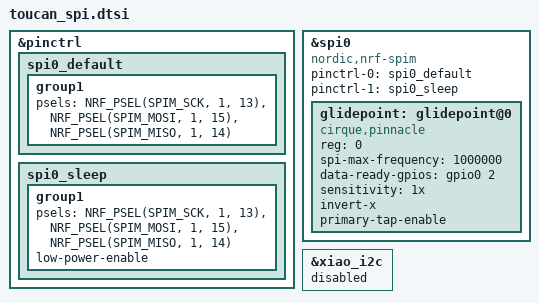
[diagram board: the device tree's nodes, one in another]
&pinctrl {
    spi0_default: spi0_default {
        group1 {
            psels = <NRF_PSEL(SPIM_SCK, 1, 13)>,
                    <NRF_PSEL(SPIM_MOSI, 1, 15)>,
                    <NRF_PSEL(SPIM_MISO, 1, 14)>;
        };
    };

    spi0_sleep: spi0_sleep {
        group1: group1 {
            psels = <NRF_PSEL(SPIM_SCK, 1, 13)>,
                    <NRF_PSEL(SPIM_MOSI, 1, 15)>,
                    <NRF_PSEL(SPIM_MISO, 1, 14)>;
            low-power-enable;
        };
    };
};

spi_node: &spi0 {
    compatible = "nordic,nrf-spim";
    status = "okay";
    pinctrl-0 = <&spi0_default>;
    pinctrl-1 = <&spi0_sleep>;
    pinctrl-names = "default", "sleep";

    glidepoint: glidepoint@0 {
        compatible = "cirque,pinnacle";
        status = "okay";
        reg = <0>;
        spi-max-frequency = <1000000>;
        data-ready-gpios = <&gpio0 2 (GPIO_ACTIVE_HIGH)>;
        sensitivity = "1x";
        invert-x;
        primary-tap-enable;
        //sleep;
    };
};

&xiao_i2c {
    status = "disabled";
};

